# MK20D5 register map
File version: 1.6
Registers are 8-bit, read-write, reset 0x0 unless marked. A register's access mark holds for its fields unless they carry their own. Offsets are from the block's base; [hi:lo] are bit positions; {n}, {i} and the like mark numbered series.

## SIM — System Integration Module
Base 0x40047000; register names take the prefix SIM_
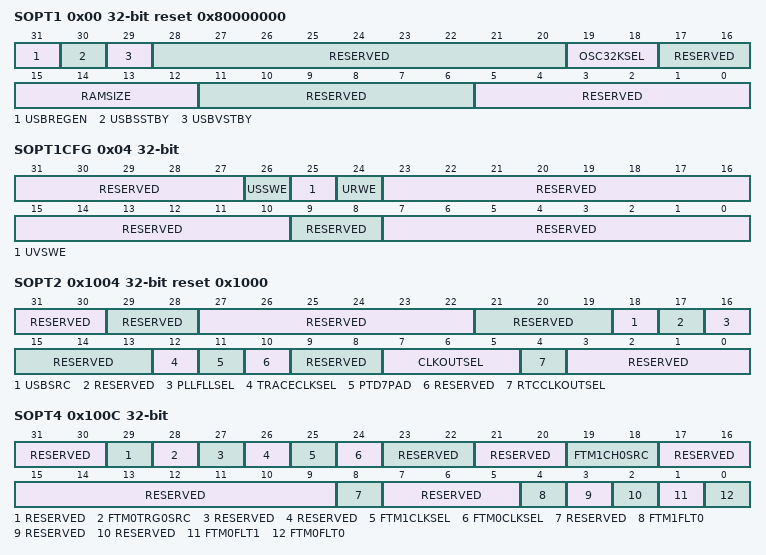
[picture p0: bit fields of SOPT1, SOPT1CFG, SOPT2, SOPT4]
0x00 SOPT1 32-bit access per field reset 0x80000000 — System Options Register 1
  [31] USBREGEN rw — USB voltage regulator enable
    0=USB voltage regulator is disabled; 1=USB voltage regulator is enabled
  [30] USBSSTBY rw — USB voltage regulator in standby mode during Stop, VLPS, LLS and VLLS modes.
    0=USB voltage regulator not in standby during Stop, VLPS, LLS and VLLS modes; 1=USB voltage regulator in standby during Stop, VLPS, LLS and VLLS modes
  [29] USBVSTBY rw — USB voltage regulator in standby mode during VLPR and VLPW modes
    0=USB voltage regulator not in standby during VLPR and VLPW modes; 1=USB voltage regulator in standby during VLPR and VLPW modes
  [28:20] RESERVED ro
  [19:18] OSC32KSEL rw — 32K oscillator clock select
    0=System oscillator (OSC32KCLK); 2=RTC 32.768kHz oscillator; 3=LPO 1 kHz
  [17:16] RESERVED ro
  [15:12] RAMSIZE ro
    0=Undefined; 1=8 KBytes; 2=Undefined; 3=16 KBytes; {v}=Undefined (v=4..15)
  [11:6] RESERVED ro
  [5:0] RESERVED ro
0x04 SOPT1CFG 32-bit access per field — SOPT1 Configuration Register
  [31:27] RESERVED ro
  [26] USSWE rw — USB voltage regulator stop standby write enable
    0=SOPT1 USBSSTB cannot be written; 1=SOPT1 USBSSTB can be written
  [25] UVSWE rw — USB voltage regulator VLP standby write enable
    0=SOPT1 USBVSTB cannot be written; 1=SOPT1 USBVSTB can be written
  [24] URWE rw — USB voltage regulator enable write enable
    0=SOPT1 USBREGEN cannot be written; 1=SOPT1 USBREGEN can be written
  [23:10] RESERVED ro
  [9:8] RESERVED ro
  [7:0] RESERVED ro
0x1004 SOPT2 32-bit access per field reset 0x1000 — System Options Register 2
  [31:30] RESERVED ro
  [29:28] RESERVED ro
  [27:22] RESERVED ro
  [21:19] RESERVED ro
  [18] USBSRC rw — USB clock source select
    0=External bypass clock (USB_CLKIN); 1=MCGPLLCLK/MCGFLLCLK clock divided by the USB fractional divider. See the SIM_CLKDIV2[USBFRAC, USBDIV] descriptions.
  [17] RESERVED ro
  [16] PLLFLLSEL rw — PLL/FLL clock select
    0=MCGFLLCLK clock; 1=MCGPLLCLK clock
  [15:13] RESERVED ro
  [12] TRACECLKSEL rw — Debug trace clock select
    0=MCGOUTCLK; 1=Core/system clock
  [11] PTD7PAD rw — PTD7 pad drive strength
    0=Single-pad drive strength for PTD7; 1=Double pad drive strength for PTD7
  [10] RESERVED ro
  [9:8] RESERVED ro
  [7:5] CLKOUTSEL rw — CLKOUT select
    2=Flash clock; 3=LPO clock (1 kHz); 4=IRCLK; 5=RTC 32.768kHz; 6=ERCLK0
  [4] RTCCLKOUTSEL rw — RTC clock out select
    0=RTC 1 Hz clock is output on the RTC_CLKOUT pin; 1=RTC 32.768kHz clock is output on the RTC_CLKOUT pin
  [3:0] RESERVED ro
0x100C SOPT4 32-bit access per field — System Options Register 4
  [31:30] RESERVED ro
  [29] RESERVED ro
  [28] FTM0TRG0SRC rw — FlexTimer 0 Hardware Trigger 0 Source Select
    0=HSCMP0 output drives FTM0 hardware trigger 0; 1=FTM1 channel match drives FTM0 hardware trigger 0
  [27] RESERVED ro
  [26] RESERVED ro
  [25] FTM1CLKSEL rw — FTM1 External Clock Pin Select
    0=FTM_CLK0 pin; 1=FTM_CLK1 pin
  [24] FTM0CLKSEL rw — FlexTimer 0 External Clock Pin Select
    0=FTM_CLK0 pin; 1=FTM_CLK1 pin
  [23:22] RESERVED ro
  [21:20] RESERVED ro
  [19:18] FTM1CH0SRC rw — FTM1 channel 0 input capture source select
    0=FTM1_CH0 signal; 1=CMP0 output; 2=CMP1 output; 3=USB start of frame pulse
  [17:9] RESERVED ro
  [8] RESERVED ro
  [7:5] RESERVED ro
  [4] FTM1FLT0 rw — FTM1 Fault 0 Select
    0=FTM1_FLT0 pin; 1=CMP0 out
  [3] RESERVED ro
  [2] RESERVED ro
  [1] FTM0FLT1 rw — FTM0 Fault 1 Select
    0=FTM0_FLT1 pin; 1=CMP1 out
  [0] FTM0FLT0 rw — FTM0 Fault 0 Select
    0=FTM0_FLT0 pin; 1=CMP0 out
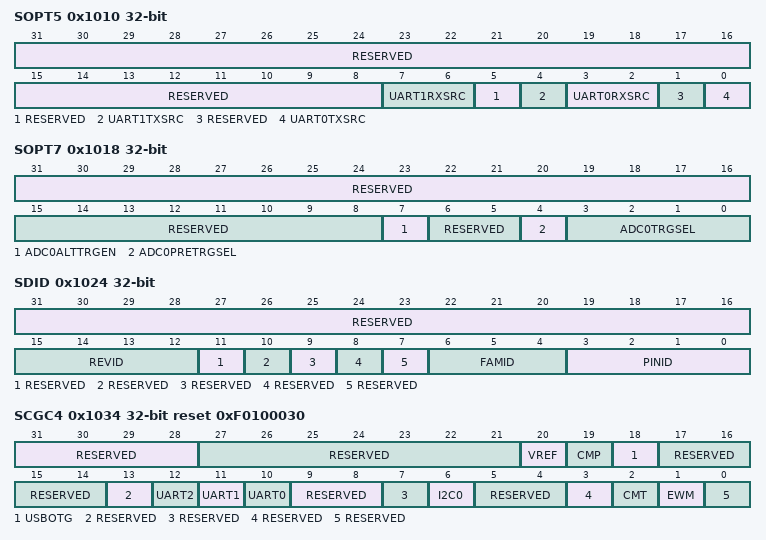
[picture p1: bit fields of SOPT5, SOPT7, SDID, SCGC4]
0x1010 SOPT5 32-bit access per field — System Options Register 5
  [31:8] RESERVED ro
  [7:6] UART1RXSRC rw — UART 1 receive data source select
    0=UART1_RX pin; 1=CMP0; 2=CMP1
  [5] RESERVED ro
  [4] UART1TXSRC rw — UART 1 transmit data source select
    0=UART1_TX pin; 1=UART1_TX pin modulated with FTM1 channel 0 output
  [3:2] UART0RXSRC rw — UART 0 receive data source select
    0=UART0_RX pin; 1=CMP0; 2=CMP1
  [1] RESERVED ro
  [0] UART0TXSRC rw — UART 0 transmit data source select
    0=UART0_TX pin; 1=UART0_TX pin modulated with FTM1 channel 0 output
0x1018 SOPT7 32-bit access per field — System Options Register 7
  [31:16] RESERVED ro
  [15:8] RESERVED ro
  [7] ADC0ALTTRGEN rw — ADC0 alternate trigger enable
    0=PDB trigger selected for ADC0; 1=Alternate trigger selected for ADC0
  [6:5] RESERVED ro
  [4] ADC0PRETRGSEL rw — ADC0 pretrigger select
    0=Pre-trigger A; 1=Pre-trigger B
  [3:0] ADC0TRGSEL rw — ADC0 trigger select
    0=PDB external trigger pin input (PDB0_EXTRG); 1=High speed comparator 0 output; 2=High speed comparator 1 output; {v}=PIT trigger {v-4} (v=4..7); 8=FTM0 trigger; 9=FTM1 trigger; 12=RTC alarm; 13=RTC seconds; 14=Low-power timer trigger
0x1024 SDID 32-bit ro reset not defined — System Device Identification Register
  [31:16] RESERVED
  [15:12] REVID — Device revision number
  [11] RESERVED
  [10] RESERVED
  [9] RESERVED
  [8] RESERVED
  [7] RESERVED
  [6:4] FAMID — Kinetis family identification
    0=K10; 1=K20
  [3:0] PINID — Pincount identification
    2=32-pin; 4=48-pin; 5=64-pin
0x1034 SCGC4 32-bit access per field reset 0xF0100030 — System Clock Gating Control Register 4
  [31:28] RESERVED ro
  [27:21] RESERVED ro
  [20] VREF rw — VREF Clock Gate Control
    0=Clock disabled; 1=Clock enabled
  [19] CMP rw — Comparator Clock Gate Control
    0=Clock disabled; 1=Clock enabled
  [18] USBOTG rw — USB Clock Gate Control
    0=Clock disabled; 1=Clock enabled
  [17:14] RESERVED ro
  [13] RESERVED ro
  [12] UART2 rw — UART2 Clock Gate Control
    0=Clock disabled; 1=Clock enabled
  [11] UART1 rw — UART1 Clock Gate Control
    0=Clock disabled; 1=Clock enabled
  [10] UART0 rw — UART0 Clock Gate Control
    0=Clock disabled; 1=Clock enabled
  [9:8] RESERVED ro
  [7] RESERVED ro
  [6] I2C0 rw — I2C0 Clock Gate Control
    0=Clock disabled; 1=Clock enabled
  [5:4] RESERVED ro
  [3] RESERVED ro
  [2] CMT rw — CMT Clock Gate Control
    0=Clock disabled; 1=Clock enabled
  [1] EWM rw — EWM Clock Gate Control
    0=Clock disabled; 1=Clock enabled
  [0] RESERVED ro
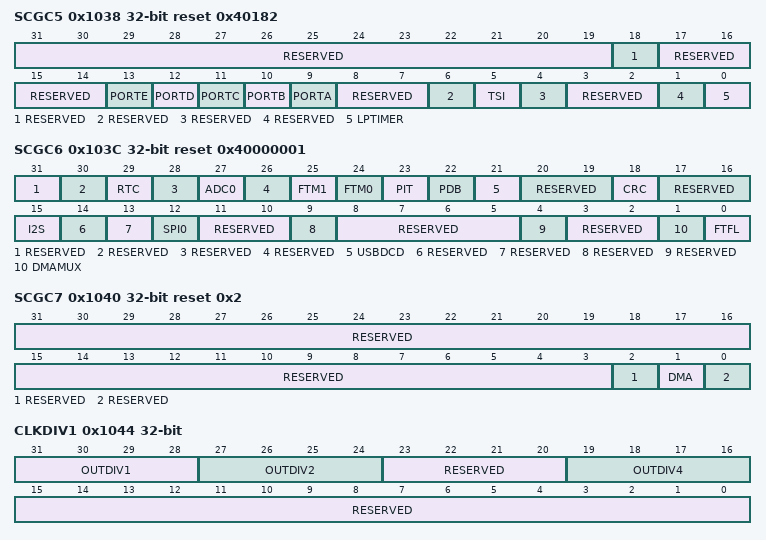
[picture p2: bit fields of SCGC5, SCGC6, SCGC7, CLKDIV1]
0x1038 SCGC5 32-bit access per field reset 0x40182 — System Clock Gating Control Register 5
  [31:19] RESERVED ro
  [18] RESERVED ro
  [17:14] RESERVED ro
  [13] PORTE rw — Port E Clock Gate Control
    0=Clock disabled; 1=Clock enabled
  [12] PORTD rw — Port D Clock Gate Control
    0=Clock disabled; 1=Clock enabled
  [11] PORTC rw — Port C Clock Gate Control
    0=Clock disabled; 1=Clock enabled
  [10] PORTB rw — Port B Clock Gate Control
    0=Clock disabled; 1=Clock enabled
  [9] PORTA rw — Port A Clock Gate Control
    0=Clock disabled; 1=Clock enabled
  [8:7] RESERVED ro
  [6] RESERVED ro
  [5] TSI rw — TSI Clock Gate Control
    0=Clock disabled; 1=Clock enabled
  [4] RESERVED ro
  [3:2] RESERVED ro
  [1] RESERVED ro
  [0] LPTIMER rw — Low Power Timer Access Control
    0=Access disabled; 1=Access enabled
0x103C SCGC6 32-bit access per field reset 0x40000001 — System Clock Gating Control Register 6
  [31] RESERVED ro
  [30] RESERVED ro
  [29] RTC rw — RTC Access Control
    0=Access and interrupts disabled; 1=Access and interrupts enabled
  [28] RESERVED ro
  [27] ADC0 rw — ADC0 Clock Gate Control
    0=Clock disabled; 1=Clock enabled
  [26] RESERVED ro
  [25] FTM1 rw — FTM1 Clock Gate Control
    0=Clock disabled; 1=Clock enabled
  [24] FTM0 rw — FTM0 Clock Gate Control
    0=Clock disabled; 1=Clock enabled
  [23] PIT rw — PIT Clock Gate Control
    0=Clock disabled; 1=Clock enabled
  [22] PDB rw — PDB Clock Gate Control
    0=Clock disabled; 1=Clock enabled
  [21] USBDCD rw — USB DCD Clock Gate Control
    0=Clock disabled; 1=Clock enabled
  [20:19] RESERVED ro
  [18] CRC rw — CRC Clock Gate Control
    0=Clock disabled; 1=Clock enabled
  [17:16] RESERVED ro
  [15] I2S rw — I2S Clock Gate Control
    0=Clock disabled; 1=Clock enabled
  [14] RESERVED ro
  [13] RESERVED ro
  [12] SPI0 rw — SPI0 Clock Gate Control
    0=Clock disabled; 1=Clock enabled
  [11:10] RESERVED ro
  [9] RESERVED ro
  [8:5] RESERVED ro
  [4] RESERVED ro
  [3:2] RESERVED ro
  [1] DMAMUX rw — DMA Mux Clock Gate Control
    0=Clock disabled; 1=Clock enabled
  [0] FTFL rw — Flash Memory Clock Gate Control
    0=Clock disabled; 1=Clock enabled
0x1040 SCGC7 32-bit access per field reset 0x2 — System Clock Gating Control Register 7
  [31:3] RESERVED ro
  [2] RESERVED ro
  [1] DMA rw — DMA Clock Gate Control
    0=Clock disabled; 1=Clock enabled
  [0] RESERVED ro
0x1044 CLKDIV1 32-bit access per field reset not defined — System Clock Divider Register 1
  [31:28] OUTDIV1 rw — Clock 1 output divider value
    {v}=Divide-by-{v+1} (v=0..15)
  [27:24] OUTDIV2 rw — Clock 2 output divider value
    {v}=Divide-by-{v+1} (v=0..15)
  [23:20] RESERVED ro
  [19:16] OUTDIV4 rw — Clock 4 output divider value
    {v}=Divide-by-{v+1} (v=0..15)
  [15:0] RESERVED ro
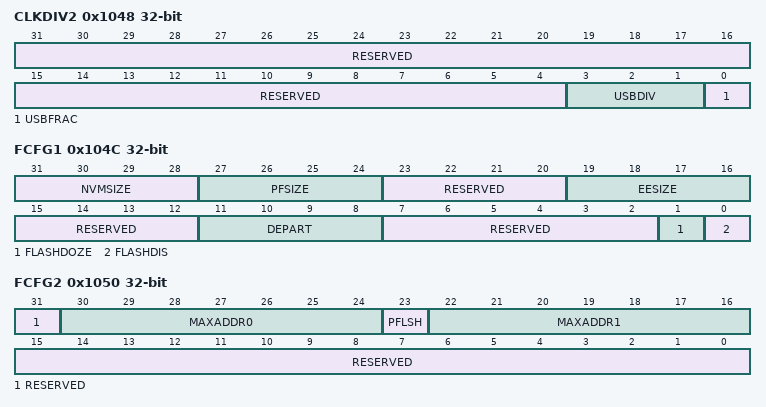
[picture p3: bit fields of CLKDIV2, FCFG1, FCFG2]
0x1048 CLKDIV2 32-bit access per field — System Clock Divider Register 2
  [31:4] RESERVED ro
  [3:1] USBDIV rw — USB clock divider divisor
  [0] USBFRAC rw — USB clock divider fraction
0x104C FCFG1 32-bit access per field reset not defined — Flash Configuration Register 1
  [31:28] NVMSIZE ro — FlexNVM size
    0=0 KB of FlexNVM; 3=32 KB of FlexNVM, 4 KB protection region
  [27:24] PFSIZE ro — Program flash size
    3=32 KB of program flash memory, 1 KB protection region; 5=64 KB of program flash memory, 2 KB protection region; 7=128 KB of program flash, 4 KB protection region
  [23:20] RESERVED ro
  [19:16] EESIZE ro — EEPROM size
    3=2 KB; 4=1 KB; 5=512 Bytes; 6=256 Bytes; 7=128 Bytes; 8=64 Bytes; 9=32 Bytes; 15=0 Bytes
  [15:12] RESERVED ro
  [11:8] DEPART ro — FlexNVM partition
  [7:2] RESERVED ro
  [1] FLASHDOZE rw
    0=Flash remains enabled during Wait mode; 1=Flash is disabled for the duration of Wait mode
  [0] FLASHDIS rw — Flash Disable
    0=Flash is enabled; 1=Flash is disabled
0x1050 FCFG2 32-bit ro reset not defined — Flash Configuration Register 2
  [31] RESERVED
  [30:24] MAXADDR0 — Max address block 0
  [23] PFLSH — Program flash
    0=Physical flash block 1 is used as FlexNVM; 1=Physical flash block 1 is used as program flash
  [22:16] MAXADDR1 — Max address block 1
  [15:0] RESERVED
0x1054 UIDH 32-bit ro reset not defined — Unique Identification Register High
  [31:0] UID — Unique Identification
0x1058 UIDMH 32-bit ro reset not defined — Unique Identification Register Mid-High
  [31:0] UID — Unique Identification
0x105C UIDML 32-bit ro reset not defined — Unique Identification Register Mid Low
  [31:0] UID — Unique Identification
0x1060 UIDL 32-bit ro reset not defined — Unique Identification Register Low
  [31:0] UID — Unique Identification
